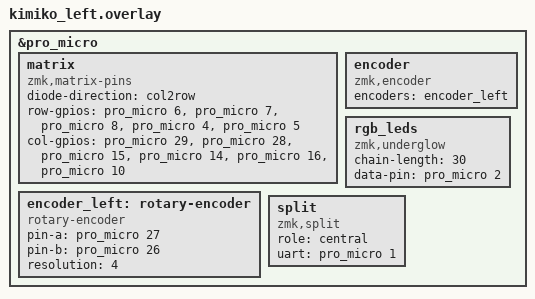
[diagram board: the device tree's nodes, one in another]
// This file was generated from a template. Edit it to match your keyboard.
// See https://zmk.dev/docs/development/hardware-integration/new-shield for more
// instructions.

#include "kimiko.dtsi"

&pro_micro {
    matrix: matrix {
        compatible = "zmk,matrix-pins";
        diode-direction = "col2row";
        row-gpios = <&pro_micro 6 GPIO_ACTIVE_HIGH>,  // C6
                    <&pro_micro 7 GPIO_ACTIVE_HIGH>,  // D7
                    <&pro_micro 8 GPIO_ACTIVE_HIGH>,  // E6
                    <&pro_micro 4 GPIO_ACTIVE_HIGH>,  // B4
                    <&pro_micro 5 GPIO_ACTIVE_HIGH>;  // B5
        col-gpios = <&pro_micro 29 GPIO_ACTIVE_HIGH>, // F6
                    <&pro_micro 28 GPIO_ACTIVE_HIGH>, // F7
                    <&pro_micro 15 GPIO_ACTIVE_HIGH>, // B1
                    <&pro_micro 14 GPIO_ACTIVE_HIGH>, // B3
                    <&pro_micro 16 GPIO_ACTIVE_HIGH>, // B2
                    <&pro_micro 10 GPIO_ACTIVE_HIGH>; // B6
    };

    encoder: encoder {
        compatible = "zmk,encoder";
        encoders = <&encoder_left>;
    };

    encoder_left: rotary-encoder {
        compatible = "rotary-encoder";
        pin-a = <&pro_micro 27>; // F5
        pin-b = <&pro_micro 26>; // F4
        resolution = <4>;
    };

    rgb_leds: rgb_leds {
        compatible = "zmk,underglow";
        chain-length = <30>;
        data-pin = <&pro_micro 2>; // D3
    };

    split {
        compatible = "zmk,split";
        role = "central";
        uart = <&pro_micro 1>; // D2
    };
};

